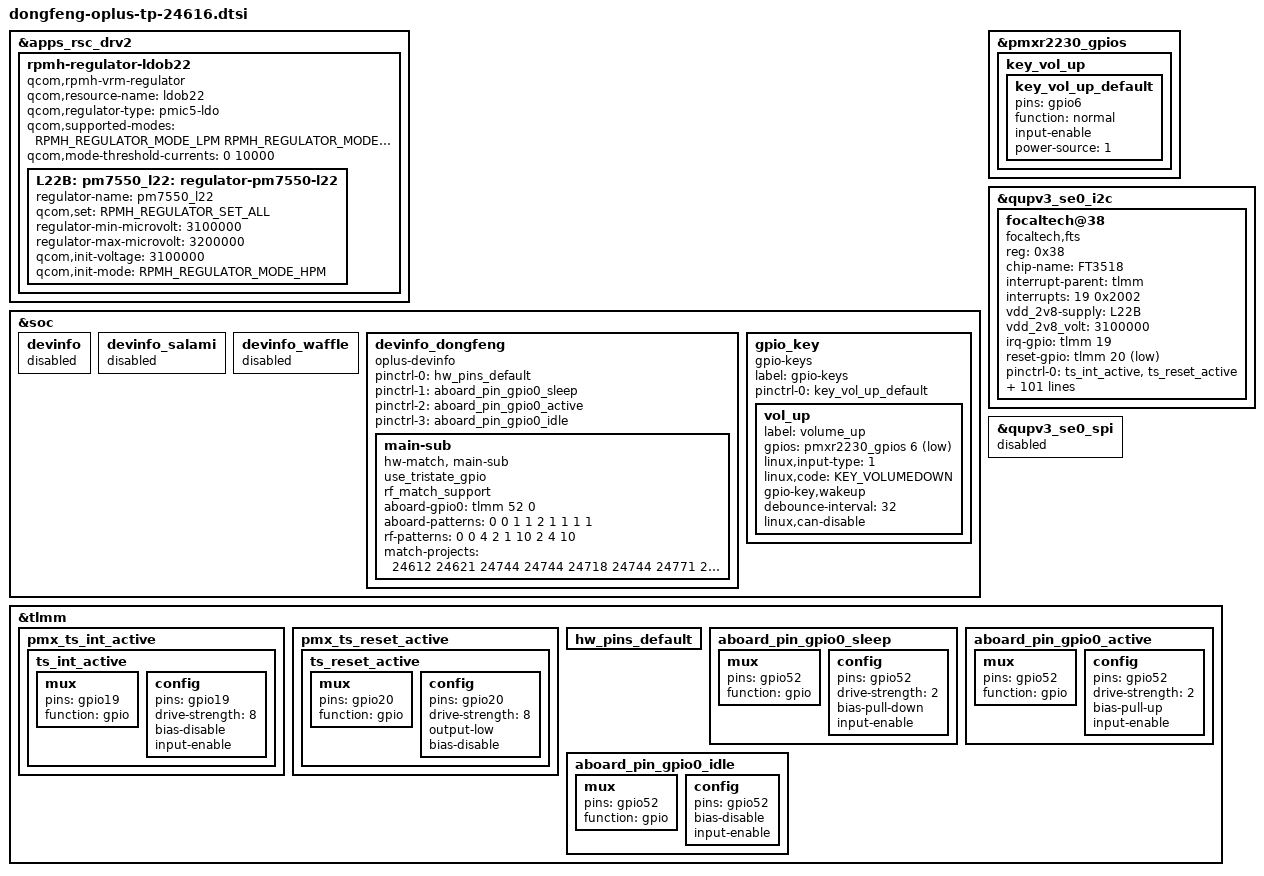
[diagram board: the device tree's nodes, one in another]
#include <dt-bindings/regulator/qcom,rpmh-regulator-levels.h>

&apps_rsc_drv2 {
	rpmh-regulator-ldob22 {
		compatible = "qcom,rpmh-vrm-regulator";
		qcom,resource-name = "ldob22";
		qcom,regulator-type = "pmic5-ldo";
		qcom,supported-modes =
			<RPMH_REGULATOR_MODE_LPM
			RPMH_REGULATOR_MODE_HPM>;
		qcom,mode-threshold-currents = <0 10000>;

		L22B:
		pm7550_l22: regulator-pm7550-l22 {
			regulator-name = "pm7550_l22";
			qcom,set = <RPMH_REGULATOR_SET_ALL>;
			regulator-min-microvolt = <3100000>;
			regulator-max-microvolt = <3200000>;
			qcom,init-voltage = <3100000>;
			qcom,init-mode = <RPMH_REGULATOR_MODE_HPM>;
		};
	};
};

&soc {

	devinfo {
		status = "disabled";
	};

	devinfo_salami {
		status = "disabled";
	};

	devinfo_waffle {
		status = "disabled";
	};

	devinfo_dongfeng {
		compatible = "oplus-devinfo";
		pinctrl-names = "default", "sleep", "active", "idle";
		pinctrl-0 = <&hw_pins_default>;
		pinctrl-1 = <&aboard_pin_gpio0_sleep>;
		pinctrl-2 = <&aboard_pin_gpio0_active>;
		pinctrl-3 = <&aboard_pin_gpio0_idle>;

		main-sub {
			compatible = "hw-match, main-sub";
			use_tristate_gpio;
			rf_match_support;
			aboard-gpio0 = <&tlmm 52 0>;
			aboard-patterns = <0 0 1 1 2 1 1 1 1>;	/*0[high-resistance] 1[pull-down] 2[pull-up]*/
			/*rf value*/
			rf-patterns = <0 0 4 2 1 10 2 4 10>;	/*0[CN] 1[IN] 2[EU] 3[NA]*/
			/*main board*/
			match-projects = <24612 24621 24744 24744 24718 24744 24771 24772 24772>;
		};
	};
};

&pmxr2230_gpios {
	/delete-node/ key_vol_up;
	key_vol_up {
		key_vol_up_default: key_vol_up_default {
			pins = "gpio6";
			function = "normal";
			input-enable;
			power-source = <1>;
		};
	};
};

&qupv3_se0_i2c {
	status = "ok";

	focaltech@38{
	    status = "okay";
		compatible = "focaltech,fts";
		reg = <0x38>;
		chip-name = "FT3518";

		/* Interrupt && Irq-gpio */
		interrupt-parent = <&tlmm>;
		interrupts = <19 0x2002>;

		/* Power Config */
		vdd_2v8-supply = <&L22B>;
		vdd_2v8_volt = <3100000>;

		/* Other HW Resource */
		irq-gpio = <&tlmm 19 0x2002>;
		reset-gpio = <&tlmm 20 0x1>;

		pinctrl-names = "default";
		pinctrl-0 = <&ts_int_active &ts_reset_active>;

		touchpanel,max-num-support = <10>;
		touchpanel,tx-rx-num = <16 34>;
		touchpanel,panel-coords = <8640 19200>;
		touchpanel,display-coords = <1080 2400>;
		touchpanel,touchmajor-limit = <0 54>;
		touchpanel,smooth-level = <255 15 40 80 160 240>;
		touchpanel,sensitive-level = <255 30 25 20 10 8>;
		touchpanel,high-frame-rate-time = <20>;
		touchpanel,single-optimized-time = <8>;

		panel_type = <8>;
		firmware_name = "AB962FT1";
		platform_support_project = <24771 24772 24718 24744 24612 24621>;
		platform_support_project_dir = <24616 24616 24616 24616 24616 24616>;
		platform_support_project_commandline = "dsi_panel_dongfeng_P_1_AB964_dsc_vid";

		prevention,curved_screen_V2;
		prevention,grip_disable_level = <6>;
		prevention,updelay_time_ms = <30>;
		prevention,makeup_cnt_weight = <4 1 2 2 2>;
		prevention,large_corner_range = <960 2400>;
		prevention,large_corner_judge_condition = <500 300 800 7 7>;
		prevention,trx_reject_condition = <9 6 7>;
		prevention,trx_strict_reject_condition = <8 5 6>;
		prevention,large_judge_time_ms = <500 50 30>;
		prevention,large_exit_condition = <8 8 2>;
		prevention,single_channel_width = <160 160>;
		prevention,normal_tap_condition = <10 350>;
		prevention,long_edge_condition = <240 80 210 80>;
		prevention,long_strict_edge_condition = <160 60>;
		prevention,long_fingerhold_condition = <50 6 4 4>;
		prevention,short_edge_condition = <240 80 210 80>;
		prevention,short_strict_edge_condition = <160 60>;
		prevention,large_strict_exit_condition = <4 4>;
		prevention,top_corner_config = <440 1200 360>;
		prevention,edge_swipe_config = <240 960>;

		prevention,curved_screen_V4;
		prevention,long_eliminate_point_type = <2 8640 6400 240 19200 300 1>;
		prevention,long_fingerhold_condition2 = <420 0 0 0>;
		prevention,top_corner_config2 = <3 80 480 0 0>;
		prevention,hor_long_top_corner_config = <240 1600 0 0>;
		prevention,top_middle_config = <8640 800 800 0>;
		prevention,corner_eliminate_point_type = <0 960 1600 1>;
		prevention,finger_hold_differ_size = <1 0 240 300>;
		prevention,finger_hold_max_rx_exit_distance = <5 240 1600>;
		prevention,max_rx_exit_distance = <1 5 150 240 1600>;
		prevention,dynamic_finger_hold_exit_distance = <1 240 1600 360>;
		prevention,edge_sliding_matched_support = <1 150 3 0>;
		//grip v4.2 reclining mode
		prevention,reclining_mode_support = <1>;
		prevention,long_eliminate_point_type_recli = <2 8640 6400 240 19200 500 0>;
		prevention,finger_hold_differ_size_recli = <1 0 240 400>;
		prevention,finger_hold_max_rx_exit_distance_recli = <4 240 1600>;
		prevention,max_rx_exit_distance_recli = <1 4 100 240 1600>;
		prevention,dynamic_finger_hold_exit_distance_recli = <1 240 1600 360>;
		prevention,edge_sliding_matched_support_recli = <1 200 3 0>;
		prevention,long_edge_condition_recli = <160 80 120 80>;

		/* SW Support Feature Control */
		black_gesture_support;
		black_gesture_indep_support;
		sportify_aod_gesture_support;
		pressure_report_support;
		charger_pump_support;
		game_switch_support;
		smart_gesture_support;
		fw_update_app_support;
		fingerprint_underscreen_support;
		fingerprint_not_report_in_suspend;
		screenoff_fingerprint_info_support;
		irq_need_dev_resume_ok;
		kernel_grip_support;
		//fw_edge_limit_support;
		exception_upload_support;
		health_monitor_support;
		//focalt x8 resolution config
		high_resolution_support;
		high_resolution_support_x8;
		disable_suspend_irq_handler_support;
		palm_to_sleep_support;
		snr_read_support;
		esd_handle_support;
		diaphragm_touch_support;
		report_rate_white_list_support;
		disable_touch_event_support;
		aiunit_game_info_support;
		/*
			*Virtual Key Config:
			*1:touchpanel,button-type: <virtualkey_type  supportted_button-map>
			*virtualkey_type:
			*Type 1: using board_properties
			*Type 2: using same IC (button zone&& touch zone are seprate)
			*Type 3: using diffrent IC (button zone&& touch zone are seprate)
			*Type 4: No need of virtual key process
			*supportted_button-map:select|menu|home|back
			*
			*2:touchpanel,button-map
			*type (X1,Y1)(X2,Y2)(X3,Y3)(Width_X,Hight_Y)--Only when button-type is 0
		*/
		touchpanel,button-type = <4>;
		touchpanel.button-TRx = <0 0>;

	};
};

&qupv3_se0_spi {
	status = "disabled";
};

&tlmm {
	pmx_ts_int_active {
		ts_int_active: ts_int_active {
			mux {
				pins = "gpio19";
				function = "gpio";
			};

			config {
				pins = "gpio19";
				drive-strength = <8>;
				bias-disable;
				input-enable;
			};
		};
	};

	pmx_ts_reset_active {
		ts_reset_active: ts_reset_active {
			mux {
				pins = "gpio20";
				function = "gpio";
			};

			config {
				pins = "gpio20";
				drive-strength = <8>;
				output-low;
				bias-disable;
			};
		};
	};

	hw_pins_default:hw_pins_default {
	};

	aboard_pin_gpio0_sleep:aboard_pin_gpio0_sleep {
		mux {
			pins = "gpio52";
			function = "gpio";
		};
		config {
			pins = "gpio52";
			drive-strength = <2>;
			bias-pull-down;
			input-enable;
		};
	};

	aboard_pin_gpio0_active:aboard_pin_gpio0_active {
		mux {
			pins = "gpio52";
			function = "gpio";
		};
		config {
			pins = "gpio52";
			drive-strength = <2>;
			bias-pull-up;
			input-enable;
		};
	};

	aboard_pin_gpio0_idle:aboard_pin_gpio0_idle {
		mux {
			pins = "gpio52";
			function = "gpio";
		};
		config {
			pins = "gpio52";
			bias-disable;
			input-enable;
		};
	};
};

&soc {
	/delete-node/ gpio_key;
	gpio_key {
		compatible = "gpio-keys";
		label = "gpio-keys";
		pinctrl-names = "default";
		pinctrl-0 = <&key_vol_up_default>;
		vol_up {
			label = "volume_up";
			gpios = <&pmxr2230_gpios 6 GPIO_ACTIVE_LOW>;
			linux,input-type = <1>;
			linux,code = <KEY_VOLUMEDOWN>;
			gpio-key,wakeup;
			debounce-interval = <32>;
			linux,can-disable;
		};
	};
};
